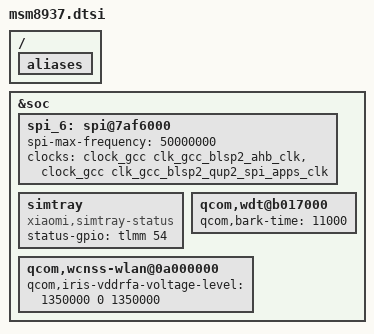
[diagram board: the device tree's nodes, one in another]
/ {
	aliases {
		/delete-property/ i2c4;
	};
};

&soc {
	/delete-node/ i2c@78b8000;

        spi_6: spi@7af6000 { /* BLSP2 QUP2 */
                spi-max-frequency = <50000000>;
		clocks = <&clock_gcc clk_gcc_blsp2_ahb_clk>,
			<&clock_gcc clk_gcc_blsp2_qup2_spi_apps_clk>;
		status = "okay";
	};
	simtray {
		compatible = "xiaomi,simtray-status";
		status-gpio = <&tlmm 54 0x00>;
	};
	qcom,wdt@b017000 {
		qcom,bark-time = <11000>;
	};
	qcom,wcnss-wlan@0a000000 {
		qcom,iris-vddrfa-voltage-level = <1350000 0 1350000>;
	};
};
